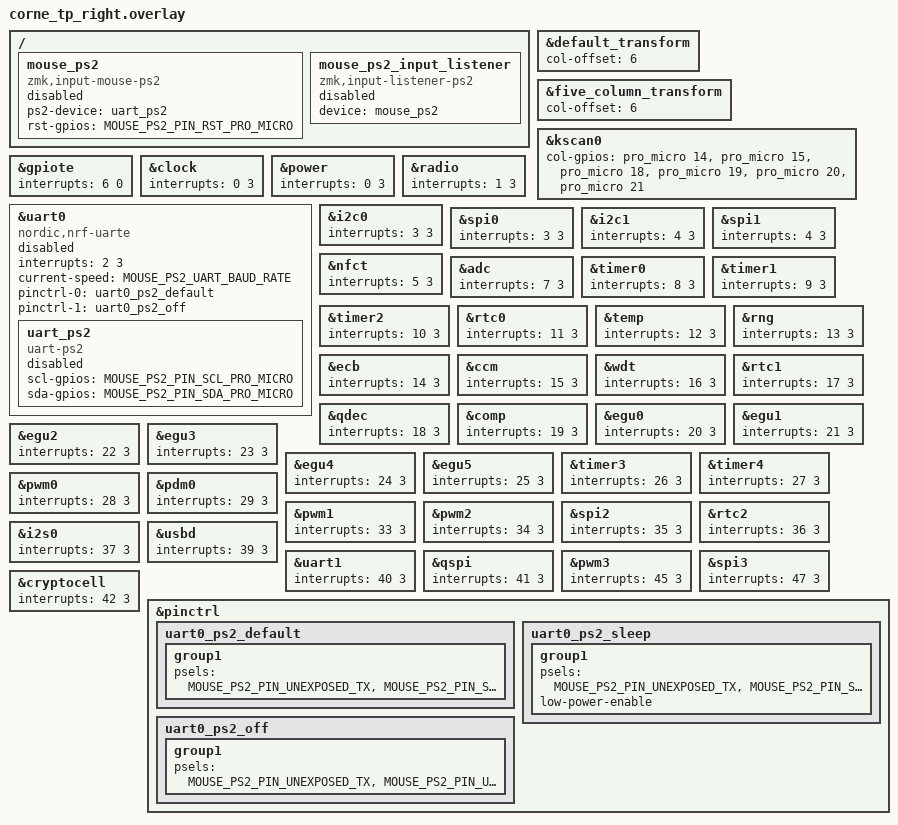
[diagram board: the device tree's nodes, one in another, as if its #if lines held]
/*
 * Copyright (c) 2020 Pete Johanson
 *
 * SPDX-License-Identifier: MIT
 */

#include "corne_tp.dtsi"

&default_transform {
    col-offset = <6>;
};

&five_column_transform {
    col-offset = <6>;
};

&kscan0 {
    col-gpios
        = <&pro_micro 14 GPIO_ACTIVE_HIGH>
        , <&pro_micro 15 GPIO_ACTIVE_HIGH>
        , <&pro_micro 18 GPIO_ACTIVE_HIGH>
        , <&pro_micro 19 GPIO_ACTIVE_HIGH>
        , <&pro_micro 20 GPIO_ACTIVE_HIGH>
        , <&pro_micro 21 GPIO_ACTIVE_HIGH>
        ;
};
// PS/2 GPIO Driver
// This uses the UART driver. Comment it out to switch to GPIO.
// For most usecases, UART is preferred.
#define MOUSE_PS2_DRIVER_UART

// Configuring SCL and SDA pins
// High frequency (blue) pins are preferred, low frequency pins will still work, but will potentially
// interfere with Bluetooth.
// Ideal pins are D1 and D0 for clock and data (high frequency)
// and D8, D9, D16, or D10 for the reset pin (if you're not using a reset circuit)
// Those are used for the backlight on default cornes, so Kim's example config uses:
// D16 and D10 for data, D9 for reset.
#define MOUSE_PS2_PIN_SCL_PRO_MICRO <&pro_micro 2 GPIO_ACTIVE_HIGH> // P0.10
#define MOUSE_PS2_PIN_SDA_PRO_MICRO <&pro_micro 1 GPIO_ACTIVE_HIGH> // P0.09

// Configuring Power-On-Reset pin
// If you have an extra free pin and your trackpoint requires POR (most of them), uncomment this.
// Low frequency pins are fine for this.
#define MOUSE_PS2_PIN_RST_PRO_MICRO <&pro_micro 3 GPIO_ACTIVE_HIGH> // P0.20

// Configuring SDA pin using pinctrl notation.
// use the same pin as in the pro micro notation, but convert to pinctrl notation 'X, Y' no leading zeros
// eg D1 - P0.08: 0, 8
// no SCL pin is necessary since UART uses baud rate, not a clock pin
#define MOUSE_PS2_PIN_SDA_PINCTRL <NRF_PSEL(UART_RX, 0, 6)>

// Configuring UART BAUD Rate
// probably not necessary, default value of 14400 should work.
// if not, try the gpio-- if it works, switch back to UART with rates of 19200 and 9600
#define MOUSE_PS2_UART_BAUD_RATE <14400>

// Don't touch these if you're using a nice!nano or clone.

// Unexposed UART pins
#define MOUSE_PS2_PIN_UNEXPOSED_TX <NRF_PSEL(UART_TX, 0, 27)>
#define MOUSE_PS2_PIN_UNEXPOSED_RX <NRF_PSEL(UART_RX, 0, 28)>

// Adjust GPIO interrupt priority to the highest level.
&gpiote {
    interrupts = < 6 0 >;
};

// All other priorities
&clock {
    interrupts = < 0 3 >;
};

&power {
    interrupts = < 0 3 >;
};

&radio {
    interrupts = < 1 3 >;
};

&uart0 {
    interrupts = < 2 3 >;
};

&i2c0 {
    interrupts = < 3 3 >;
};

&spi0 {
    interrupts = < 3 3 >;
};

&i2c1 {
    interrupts = < 4 3 >;
};

&spi1 {
    interrupts = < 4 3 >;
};

&nfct {
    interrupts = < 5 3 >;
};

&adc {
    interrupts = < 7 3 >;
};
 
&timer0 {
    interrupts = < 8 3 >;
};

&timer1 {
    interrupts = < 9 3 >;
};

&timer2 {
    interrupts = < 10 3 >;
};

&rtc0 {
    interrupts = < 11 3 >;
};

&temp {
    interrupts = < 12 3 >;
};

&rng {
    interrupts = < 13 3 >;
};

&ecb {
    interrupts = < 14 3 >;
};

&ccm {
    interrupts = < 15 3 >;
};

&wdt {
    interrupts = < 16 3 >;
};

&rtc1 {
    interrupts = < 17 3 >;
};

&qdec {
    interrupts = < 18 3 >;
};

&comp {
    interrupts = < 19 3 >;
};

&egu0 {
    interrupts = < 20 3 >;
};

&egu1 {
    interrupts = < 21 3 >;
};

&egu2 {
    interrupts = < 22 3 >;
};

&egu3 {
    interrupts = < 23 3 >;
};

&egu4 {
    interrupts = < 24 3 >;
};

&egu5 {
    interrupts = < 25 3 >;
};

&timer3 {
    interrupts = < 26 3 >;
};

&timer4 {
    interrupts = < 27 3 >;
};

&pwm0 {
    interrupts = < 28 3 >;
};

&pdm0 {
    interrupts = < 29 3 >;
};

&pwm1 {
    interrupts = < 33 3 >;
};

&pwm2 {
    interrupts = < 34 3 >;
};

&spi2 {
    interrupts = < 35 3 >;
};

&rtc2 {
    interrupts = < 36 3 >;
};

&i2s0 {
    interrupts = < 37 3 >;
};

&usbd {
    interrupts = < 39 3 >;
};

&uart1 {
    interrupts = < 40 3 >;
};

&qspi {
    interrupts = < 41 3 >;
};

&pwm3 {
    interrupts = < 45 3 >;
};

&spi3 {
    interrupts = < 47 3 >;
};
 
&cryptocell {
    interrupts = < 42 3 >;
};

// PS/2 Mouse / Trackpoint - Device Definitions
// Don't touch this unless you know what you're doing .

// Firmware with alternative pins
//
// This can safely be removed. It's only used in the example zmk-config repo
// to create an additional firmware with alternative PIN assignments.
//
// You can leave it or remove in your own zmk config. If you remove it, you
// should also remove the entry in `zmk-config-example/build.yaml` that uses
// it.
#ifdef MOUSE_PS2_ALT_PINS
    #undef MOUSE_PS2_PIN_SCL_PRO_MICRO
    #undef MOUSE_PS2_PIN_SDA_PRO_MICRO
    #undef MOUSE_PS2_PIN_SDA_PINCTRL

    #define MOUSE_PS2_PIN_SCL_PRO_MICRO <&pro_micro 2 GPIO_ACTIVE_HIGH> // P0.17
    #define MOUSE_PS2_PIN_SDA_PRO_MICRO <&pro_micro 1 GPIO_ACTIVE_HIGH> // P0.20
    #define MOUSE_PS2_PIN_SDA_PINCTRL <NRF_PSEL(UART_RX, 0, 6)>
#endif

#define MOUSE_PS2_DT_PRESENT

&pinctrl {
	uart0_ps2_default: uart0_ps2_default {
		group1 {
			psels = MOUSE_PS2_PIN_UNEXPOSED_TX,
					MOUSE_PS2_PIN_SDA_PINCTRL;
		};
	};
	uart0_ps2_sleep: uart0_ps2_sleep {
		group1 {
			psels = MOUSE_PS2_PIN_UNEXPOSED_TX,
					MOUSE_PS2_PIN_SDA_PINCTRL;
			low-power-enable;
		};
	};
	uart0_ps2_off: uart0_ps2_off {
		group1 {
			psels = MOUSE_PS2_PIN_UNEXPOSED_TX,
					MOUSE_PS2_PIN_UNEXPOSED_RX;
		};
	};
};


#ifdef MOUSE_PS2_DRIVER_UART

    &uart0 {
        status = "disabled";
        compatible = "nordic,nrf-uarte";

        current-speed = MOUSE_PS2_UART_BAUD_RATE;
        pinctrl-0 = <&uart0_ps2_default>;
        pinctrl-1 = <&uart0_ps2_off>;

        pinctrl-names = "default", "sleep";

        uart_ps2: uart_ps2 {
            status="disabled";
            compatible = "uart-ps2";
            scl-gpios = MOUSE_PS2_PIN_SCL_PRO_MICRO;
            sda-gpios = MOUSE_PS2_PIN_SDA_PRO_MICRO;
        };
    };

#else

    / {
        gpio_ps2: gpio_ps2 {
            status = "disabled";
            compatible = "gpio-ps2";
            scl-gpios = MOUSE_PS2_PIN_SCL_PRO_MICRO;
            sda-gpios = MOUSE_PS2_PIN_SDA_PRO_MICRO;
        };
    };

#endif

/ {
    mouse_ps2: mouse_ps2 {
		status = "disabled";
        compatible = "zmk,input-mouse-ps2";

#ifdef MOUSE_PS2_DRIVER_UART
	    ps2-device = <&uart_ps2>;
#else
	    ps2-device = <&gpio_ps2>;
#endif

#ifdef MOUSE_PS2_PIN_RST_PRO_MICRO
        rst-gpios = MOUSE_PS2_PIN_RST_PRO_MICRO;
#endif
    };

    mouse_ps2_input_listener: mouse_ps2_input_listener {
        compatible = "zmk,input-listener-ps2";
        status = "disabled";
        device = <&mouse_ps2>;
		// Some of the available settings depend on the keymap. So they
		// are adjusted in...
		// zmk-config/config/includes/mouse_tp.dtsi
    };
};
